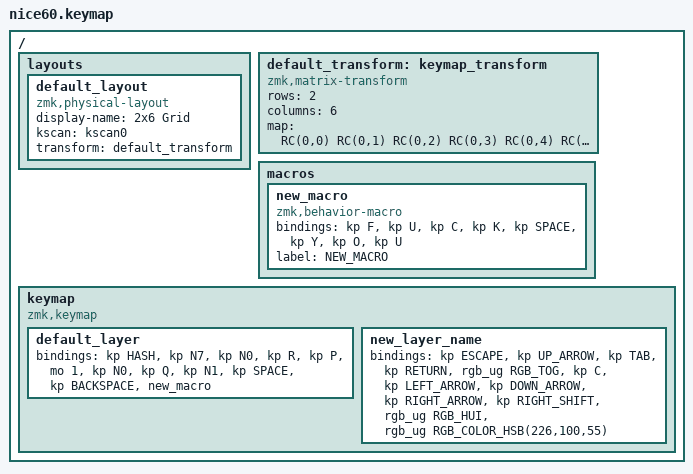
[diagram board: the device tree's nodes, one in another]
#include <behaviors.dtsi>
#include <dt-bindings/zmk/keys.h>
#include <dt-bindings/zmk/rgb.h>

/ {
    layouts {
        default_layout {
            compatible = "zmk,physical-layout";
            display-name = "2x6 Grid";
            kscan = <&kscan0>;
            transform = <&default_transform>;
        };
    };

    default_transform: keymap_transform {
        compatible = "zmk,matrix-transform";
        rows = <2>;
        columns = <6>;
        map = <
            RC(0,0) RC(0,1) RC(0,2) RC(0,3) RC(0,4) RC(0,5)
            RC(1,0) RC(1,1) RC(1,2) RC(1,3) RC(1,4) RC(1,5)
        >;
    };

    macros {
        new_macro: new_macro {
            compatible = "zmk,behavior-macro";
            #binding-cells = <0>;
            bindings = <&kp F &kp U &kp C &kp K &kp SPACE &kp Y &kp O &kp U>;
            label = "NEW_MACRO";
        };
    };

    keymap {
        compatible = "zmk,keymap";

        default_layer {
            bindings = <
&kp HASH  &kp N7  &kp N0  &kp R  &kp P  &mo 1  &kp N0  &kp Q  &kp N1  &kp SPACE  &kp BACKSPACE  &new_macro
            >;
        };

        new_layer_name {
            bindings = <
&kp ESCAPE  &kp UP_ARROW  &kp TAB  &kp RETURN  &rgb_ug RGB_TOG  &kp C  &kp LEFT_ARROW  &kp DOWN_ARROW  &kp RIGHT_ARROW  &kp RIGHT_SHIFT  &rgb_ug RGB_HUI  &rgb_ug RGB_COLOR_HSB(226,100,55)
            >;
        };
    };
};
